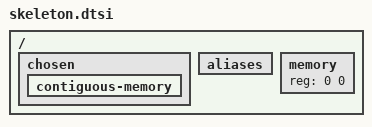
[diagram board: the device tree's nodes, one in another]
/*
 * Skeleton device tree; the bare minimum needed to boot; just include and
 * add a compatible value.  The bootloader will typically populate the memory
 * node.
 */

/ {
	#address-cells = <1>;
	#size-cells = <1>;
	chosen {
		contiguous-memory {
			#address-cells = <1>;
			#size-cells = <1>;
		};
	};
	aliases { };
	memory { device_type = "memory"; reg = <0 0>; };
};

